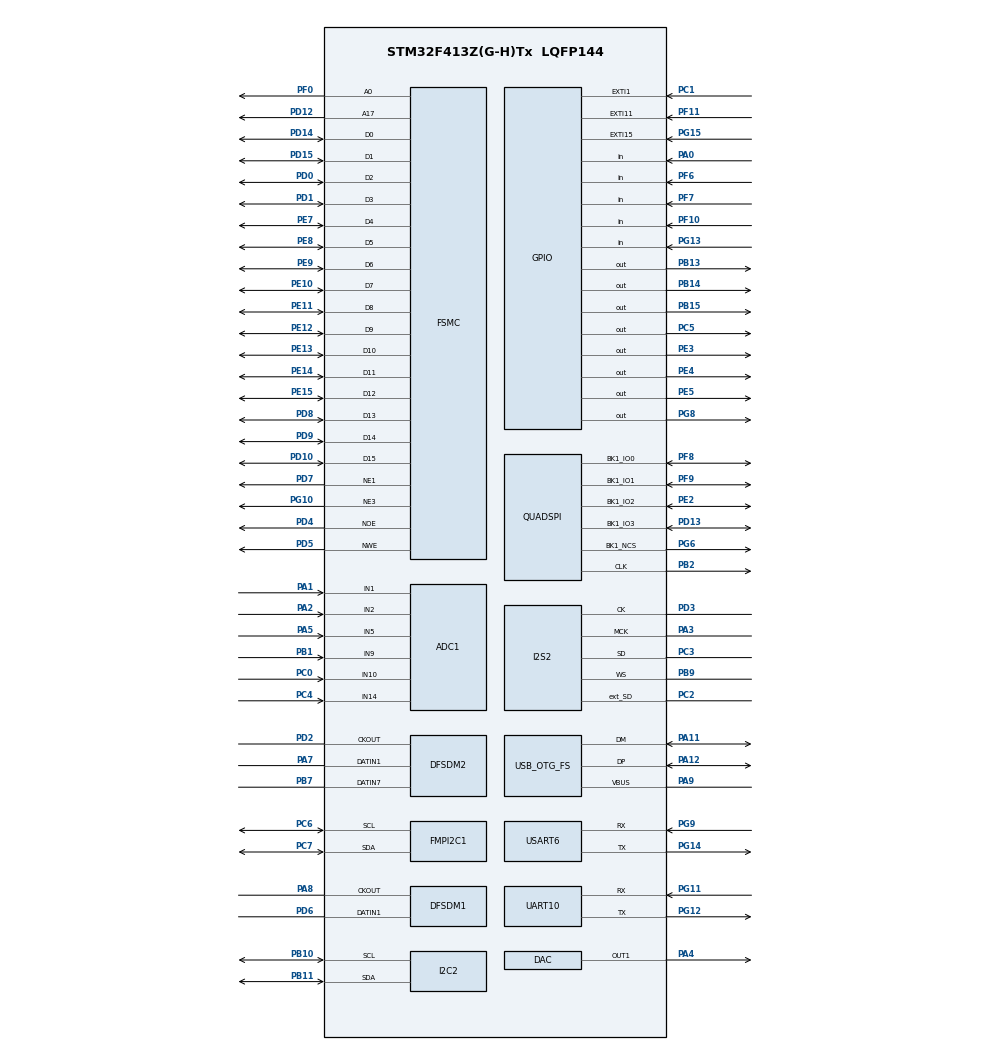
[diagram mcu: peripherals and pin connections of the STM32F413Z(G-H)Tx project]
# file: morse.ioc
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SH.FSMC_D1_DA1.1=FSMC_D1,16b-d2
PD7.Mode=NorPsramChipSelect1_1
PF5.GPIO_PuPd=GPIO_NOPULL
PG8.GPIO_ModeDefaultOutputPP=GPIO_MODE_OUTPUT_PP
SH.FSMC_D1_DA1.0=FSMC_D1,16b-d1
PC10.GPIO_PuPd=GPIO_NOPULL
NVIC.TIM6_DAC_IRQn=true\:0\:0\:false\:false\:true\:false\:false\:true
PA10.GPIO_PuPd=GPIO_NOPULL
PG8.Signal=GPIO_Output
SH.FSMC_NWE.0=FSMC_NWE,Lcd1
PG0.Signal=FSMC_A10
PA3.GPIO_PuPd=GPIO_NOPULL
SH.FSMC_NWE.1=FSMC_NWE,Lcd2
PE8.GPIO_Speed_High_Default=GPIO_SPEED_FREQ_VERY_HIGH
PE10.GPIO_PuPd=GPIO_NOPULL
PD10.GPIO_PuPd=GPIO_NOPULL
USB_HOST.USBH_USE_OS-CDC_FS=0
PG10.GPIO_PuPd=GPIO_NOPULL
PA6.GPIO_Mode=GPIO_MODE_AF_PP
PD0.GPIO_Speed_High_Default=GPIO_SPEED_FREQ_VERY_HIGH
PE13.GPIO_Mode=GPIO_MODE_AF_PP
PF13.GPIO_Mode=GPIO_MODE_AF_PP
PF7.Signal=GPIO_Input
PD13.GPIO_Mode=GPIO_MODE_AF_PP
PD7.GPIO_PuPd=GPIO_NOPULL
PD9.GPIO_Speed_High_Default=GPIO_SPEED_FREQ_VERY_HIGH
PC4.GPIO_Mode=GPIO_MODE_ANALOG
PC7.Signal=FMPI2C1_SDA
PD0.Signal=FSMC_D2_DA2
PD8.Signal=FSMC_D13_DA13
PE1.Signal=FSMC_NBL1
PG5.GPIO_Speed_High_Default=GPIO_SPEED_FREQ_VERY_HIGH
USB_OTG_FS.phy_itface=HCD_PHY_EMBEDDED
PC1.GPIO_PuPd=GPIO_NOPULL
PG14.Mode=Asynchronous
SH.FSMC_D10_DA10.0=FSMC_D10,16b-d1
PE9.Signal=FSMC_D6_DA6
SH.FSMC_D10_DA10.1=FSMC_D10,16b-d2
PD14.GPIO_PuPd=GPIO_NOPULL
PA8.Signal=S_CKOUTDFSDM1
PG4.GPIO_Speed_High_Default=GPIO_SPEED_FREQ_VERY_HIGH
PF1.GPIO_Mode=GPIO_MODE_AF_PP
PF14.GPIO_PuPd=GPIO_NOPULL
SH.FSMC_D5_DA5.0=FSMC_D5,16b-d1
PG0.GPIO_PuPd=GPIO_NOPULL
PB2.GPIO_PuPd=GPIO_NOPULL
SH.FSMC_D5_DA5.1=FSMC_D5,16b-d2
PA0.Signal=GPIO_Input
PE9.GPIO_Mode=GPIO_MODE_AF_PP
Mcu.Package=LQFP144
PE2.GPIO_Mode=GPIO_MODE_AF_PP
PB9.Signal=I2S2_WS
PB1.Signal=ADCx_IN9
PB14.GPIO_PuPd=GPIO_NOPULL
NVIC.TimeBase=TIM6_DAC_IRQn
PD12.Signal=FSMC_A17
PG3.GPIO_Mode=GPIO_MODE_AF_PP
NVIC.TimeBaseIP=TIM6
PA10.Signal=USB_OTG_FS_ID
PB9.GPIO_PuPd=GPIO_NOPULL
SH.FSMC_A1.0=FSMC_A1
PB5.GPIO_Speed=GPIO_SPEED_FREQ_VERY_HIGH
PG8.GPIO_Speed=GPIO_SPEED_FREQ_LOW
PD3.GPIO_PuPd=GPIO_NOPULL
PF9.GPIO_PuPd=GPIO_NOPULL
PE6.GPIO_PuPd=GPIO_NOPULL
PA8.GPIO_Speed=GPIO_SPEED_FREQ_LOW
PD15.Signal=FSMC_D1_DA1
PE7.GPIO_Speed_High_Default=GPIO_SPEED_FREQ_VERY_HIGH
PC8.GPIO_Mode=GPIO_MODE_AF_PP
PG12.Signal=UART10_TX
PA2.GPIO_Mode=GPIO_MODE_ANALOG
PB5.GPIO_Mode=GPIO_MODE_AF_PP
FREERTOS.Tasks01=gameTask,24,128,gameHandler,Default,NULL,Dynamic,NULL,NULL;displayTask,8,128,displayHandler,Default,NULL,Dynamic,NULL,NULL;buttonTask,8,128,buttonHandler,Default,NULL,Dynamic,NULL,NULL;ledTask,8,128,ledHandler,Default,NULL,Dynamic,NULL,NULL;runIndicate,8,128,runIndicateHandler,Default,NULL,Dynamic,NULL,NULL
SH.FSMC_A16.0=FSMC_A16
PF4.GPIO_Mode=GPIO_MODE_AF_PP
PD1.GPIO_Speed_High_Default=GPIO_SPEED_FREQ_VERY_HIGH
PG5.Signal=FSMC_A15
PE9.GPIO_Speed_High_Default=GPIO_SPEED_FREQ_VERY_HIGH
PD3.Signal=I2S2_CK
SH.FSMC_D9_DA9.1=FSMC_D9,16b-d2
PH1\ -\ OSC_OUT.Mode=HSE-External-Clock-Source
PG9.Mode=Asynchronous
PC2.Signal=I2S2_ext_SD
SH.FSMC_D9_DA9.0=FSMC_D9,16b-d1
PC14-OSC32_IN.Signal=RCC_OSC32_IN
PF5.GPIO_Mode=GPIO_MODE_AF_PP
SH.FSMC_D8_DA8.0=FSMC_D8,16b-d1
SH.FSMC_D8_DA8.1=FSMC_D8,16b-d2
PG8.GPIO_PuPd=GPIO_NOPULL
PD10.Signal=FSMC_D15_DA15
PA3.Mode=Master_Clock_Activated
PC10.GPIO_Mode=GPIO_MODE_AF_PP
PE15.GPIO_Speed_High_Default=GPIO_SPEED_FREQ_VERY_HIGH
PB10.GPIO_Mode=GPIO_MODE_AF_OD
SH.FSMC_A3.0=FSMC_A3
PB1.GPIO_Mode=GPIO_MODE_ANALOG
PB13.GPIO_Speed=GPIO_SPEED_FREQ_LOW
PF5.GPIO_Speed_High_Default=GPIO_SPEED_FREQ_VERY_HIGH
PD7.GPIO_Mode=GPIO_MODE_AF_PP
PG10.GPIO_Mode=GPIO_MODE_AF_PP
PB14.Signal=GPIO_Output
PA5.Signal=ADCx_IN5
PE2.GPIO_PuPd=GPIO_NOPULL
PD14.GPIO_Speed_High_Default=GPIO_SPEED_FREQ_VERY_HIGH
PF13.GPIO_PuPd=GPIO_NOPULL
PB13.GPIO_PuPd=GPIO_NOPULL
PE14.Signal=FSMC_D11_DA11
PB2.GPIO_Mode=GPIO_MODE_AF_PP
PG15.GPIO_ModeDefaultEXTI=GPIO_MODE_IT_RISING
PC9.GPIO_PuPd=GPIO_NOPULL
PE3.GPIO_PuPd=GPIO_NOPULL
PF13.Signal=FSMC_A7
PG14.GPIO_PuPd=GPIO_NOPULL
PC8.GPIO_PuPd=GPIO_NOPULL
ADC1.master=1
PB5.GPIO_PuPd=GPIO_NOPULL
ProjectManager.HeapSize=0x200
PD0.GPIO_PuPd=GPIO_NOPULL
PG12.GPIO_Speed=GPIO_SPEED_FREQ_VERY_HIGH
USB_HOST.USBH_HandleTypeDef=hUsbHostFS
NVIC.PriorityGroup=NVIC_PRIORITYGROUP_4
SH.FSMC_A5.0=FSMC_A5
PC5.GPIO_Speed=GPIO_SPEED_FREQ_LOW
PC1.GPIO_ModeDefaultEXTI=GPIO_MODE_IT_RISING
PE3.Signal=GPIO_Output
PE4.PinState=GPIO_PIN_RESET
PA6.GPIO_Speed_High_Default=GPIO_SPEED_FREQ_VERY_HIGH
PF4.Signal=FSMC_A4
PD2.Signal=S_CKOUTDFSDM2
PD14.GPIO_Mode=GPIO_MODE_AF_PP
Mcu.Family=STM32F4
PD7.GPIO_Speed_High_Default=GPIO_SPEED_FREQ_VERY_HIGH
FREERTOS.BinarySemaphores01=displaySemEMPTY,Dynamic,NULL;displaySemFULL,Dynamic,NULL;buttonSemFULL,Dynamic,NULL;buttonSemEMPTY,Dynamic,NULL;ledSemFULL,Dynamic,NULL;ledSEMEmpty,Dynamic,NULL
SH.FSMC_A6.0=FSMC_A6
PG2.Signal=FSMC_A12
PB2.GPIO_Speed=GPIO_SPEED_FREQ_VERY_HIGH
PA7.GPIO_Mode=GPIO_MODE_AF_PP
SH.FSMC_D0_DA0.1=FSMC_D0,16b-d2
PE2.GPIO_Speed=GPIO_SPEED_FREQ_VERY_HIGH
SH.FSMC_D0_DA0.0=FSMC_D0,16b-d1
PA11.Mode=Host_Only
PF9.GPIO_Speed=GPIO_SPEED_FREQ_VERY_HIGH
PD2.GPIO_Mode=GPIO_MODE_AF_PP
PC2.GPIO_Speed=GPIO_SPEED_FREQ_LOW
PG9.GPIO_Speed=GPIO_SPEED_FREQ_VERY_HIGH
PD8.GPIO_PuPd=GPIO_NOPULL
PB15.Signal=GPIO_Output
PG11.Signal=UART10_RX
PG15.Signal=GPXTI15
PG3.GPIO_PuPd=GPIO_NOPULL
PD13.Signal=QUADSPI_BK1_IO3
SH.S_DATAIN7DFSDM2.0=DFSDM2_DATIN7,Manchester_input_from_ch7
PC11.GPIO_PuPd=GPIO_NOPULL
SH.FSMC_A11.0=FSMC_A11
PH0\ -\ OSC_IN.Signal=RCC_OSC_IN
PE11.GPIO_PuPd=GPIO_NOPULL
PF11.GPIO_PuPd=GPIO_NOPULL
PB1.GPIO_PuPd=GPIO_NOPULL
PG5.GPIO_PuPd=GPIO_NOPULL
USB_HOST0.BSP.ip=GPIO
PA15.GPIO_ModeDefaultPP=GPIO_MODE_AF_PP
PF15.GPIO_Speed_High_Default=GPIO_SPEED_FREQ_VERY_HIGH
PE3.PinState=GPIO_PIN_RESET
PD4.GPIO_Mode=GPIO_MODE_AF_PP
PA9.GPIO_Mode=GPIO_MODE_INPUT
ADC1.Channel-0\#ChannelRegularConversion=ADC_CHANNEL_10
PA4.GPIO_PuPd=GPIO_NOPULL
PE13.GPIO_PuPd=GPIO_NOPULL
SH.FSMC_NBL0.0=FSMC_NBL0
PG11.GPIO_Speed=GPIO_SPEED_FREQ_VERY_HIGH
PA6.GPIO_PuPd=GPIO_NOPULL
SH.FSMC_D14_DA14.1=FSMC_D14,16b-d2
PF9.Mode=Single Bank 1
SH.FSMC_D14_DA14.0=FSMC_D14,16b-d1
PC14-OSC32_IN.Mode=LSE-External-Oscillator
PF8.GPIO_PuPd=GPIO_NOPULL
PA14.Mode=Serial_Wire
PF11.Signal=GPXTI11
SH.FSMC_D6_DA6.0=FSMC_D6,16b-d1
SH.FSMC_D6_DA6.1=FSMC_D6,16b-d2
PC7.GPIO_Mode=GPIO_MODE_AF_OD
SH.FSMC_A8.0=FSMC_A8
PB7.Signal=S_DATAIN7DFSDM2
PG4.GPIO_Mode=GPIO_MODE_AF_PP
SH.FSMC_D4_DA4.1=FSMC_D4,16b-d2
SH.FSMC_D4_DA4.0=FSMC_D4,16b-d1
PD6.GPIO_Mode=GPIO_MODE_AF_PP
PB12.GPIO_Mode=GPIO_MODE_AF_PP
PA6.Signal=SDIO_CMD
PB15.GPIO_PuPd=GPIO_NOPULL
PG2.GPIO_Speed_High_Default=GPIO_SPEED_FREQ_VERY_HIGH
USART6.VirtualMode=VM_ASYNC
NVIC.OTG_FS_IRQn=true\:0\:0\:false\:false\:true\:true\:true\:true
PG1.GPIO_PuPd=GPIO_NOPULL
FMPI2C1.Timing=0x00303D5B
SH.FSMC_D13_DA13.0=FSMC_D13,16b-d1
SH.FSMC_D13_DA13.1=FSMC_D13,16b-d2
PA15.Signal=S_TIM2_CH1_ETR
PF8.Signal=QUADSPI_BK1_IO0
SH.FSMC_A13.0=FSMC_A13
PA10.GPIO_Speed=GPIO_SPEED_FREQ_VERY_HIGH
USB_HOST0.BSP.name=Drive_VBUS_FS
SH.ADCx_IN1.0=ADC1_IN1,IN1
PD0.GPIO_Mode=GPIO_MODE_AF_PP
SH.FSMC_D2_DA2.1=FSMC_D2,16b-d2
SH.FSMC_D2_DA2.0=FSMC_D2,16b-d1
PC5.Signal=GPIO_Output
PE14.GPIO_Mode=GPIO_MODE_AF_PP
PE7.Signal=FSMC_D4_DA4
PD6.Signal=S_DATAIN1DFSDM1
SH.S_DATAIN1DFSDM1.0=DFSDM1_DATIN1,Manchester_input_from_ch1
PA12.GPIO_Speed=GPIO_SPEED_FREQ_VERY_HIGH
PB4.Signal=SPI3_MISO
PA3.Signal=I2S2_MCK
PE0.GPIO_PuPd=GPIO_NOPULL
PG1.GPIO_Mode=GPIO_MODE_AF_PP
SH.FSMC_D12_DA12.0=FSMC_D12,16b-d1
SH.FSMC_D12_DA12.1=FSMC_D12,16b-d2
PC11.Signal=SDIO_D3
PD12.GPIO_Speed_High_Default=GPIO_SPEED_FREQ_VERY_HIGH
PC8.Signal=SDIO_D0
USB_HOST0.BSP.solution=PG8
PC2.Mode=Full_Duplex_Master
PD9.Signal=FSMC_D14_DA14
PD8.GPIO_Speed_High_Default=GPIO_SPEED_FREQ_VERY_HIGH
SH.S_TIM3_CH3.0=TIM3_CH3
PA9.GPIO_PuPd=GPIO_NOPULL
PB0.GPIO_Speed=GPIO_SPEED_FREQ_LOW
PA13.Signal=SYS_JTMS-SWDIO
PD4.GPIO_PuPd=GPIO_NOPULL
PA9.Mode=Activate_VBUS
PH0\ -\ OSC_IN.Mode=HSE-External-Clock-Source
PB14.PinState=GPIO_PIN_RESET
PF6.Signal=GPIO_Input
PC9.GPIO_Mode=GPIO_MODE_AF_PP
PF0.GPIO_Speed_High_Default=GPIO_SPEED_FREQ_VERY_HIGH
PA3.GPIO_Mode=GPIO_MODE_AF_PP
SH.S_TIM4_CH3.0=TIM4_CH3
PB9.Mode=Full_Duplex_Master
PG2.GPIO_Mode=GPIO_MODE_AF_PP
RCC.USBFreq_Value=48000000
PB14.GPIO_ModeDefaultOutputPP=GPIO_MODE_OUTPUT_PP
PA7.GPIO_PuPd=GPIO_NOPULL
PA1.Signal=ADCx_IN1
PE10.GPIO_Speed_High_Default=GPIO_SPEED_FREQ_VERY_HIGH
PE10.GPIO_Mode=GPIO_MODE_AF_PP
board=STM32F413H-DISCO
PD13.GPIO_Speed=GPIO_SPEED_FREQ_VERY_HIGH
PG12.Mode=Asynchronous
PC7.GPIO_Speed=GPIO_SPEED_FREQ_VERY_HIGH
RCC.VCOOutputFreq_Value=240000000
PA4.GPIO_Mode=GPIO_MODE_ANALOG
PG3.GPIO_Speed_High_Default=GPIO_SPEED_FREQ_VERY_HIGH
PE11.GPIO_Mode=GPIO_MODE_AF_PP
PD5.GPIO_PuPd=GPIO_NOPULL
PE14.GPIO_PuPd=GPIO_NOPULL
PF1.Signal=FSMC_A1
PF8.GPIO_Mode=GPIO_MODE_AF_PP
PE0.Signal=FSMC_NBL0
PE12.Signal=FSMC_D9_DA9
PE12.GPIO_Mode=GPIO_MODE_AF_PP
I2S2.ErrorAudioFreq=1.72 %
VP_USB_HOST_VS_USB_HOST_CDC_FS.Mode=CDC_FS
PB2.Mode=Single Bank 1
PA15.GPIO_Speed=GPIO_SPEED_FREQ_LOW
PE15.GPIO_PuPd=GPIO_NOPULL
PE5.GPIO_ModeDefaultOutputPP=GPIO_MODE_OUTPUT_PP
SH.FSMC_D11_DA11.1=FSMC_D11,16b-d2
SH.FSMC_D11_DA11.0=FSMC_D11,16b-d1
SH.FSMC_NOE.1=FSMC_NOE,Lcd2
PG4.GPIO_PuPd=GPIO_NOPULL
SH.FSMC_NOE.0=FSMC_NOE,Lcd1
PD3.GPIO_Mode=GPIO_MODE_AF_PP
PA8.GPIO_PuPd=GPIO_NOPULL
PF9.GPIO_Mode=GPIO_MODE_AF_PP
SH.S_CKOUTDFSDM2.0=DFSDM2_CKOUT,CKOUT
RCC.PLLQ=5
RCC.PLLM=15
RCC.PLLN=144
PE5.GPIO_Speed=GPIO_SPEED_FREQ_LOW
PG0.GPIO_Mode=GPIO_MODE_AF_PP
PA5.GPIO_Mode=GPIO_MODE_ANALOG
PB8.GPIO_Speed=GPIO_SPEED_FREQ_LOW
PD6.GPIO_Speed=GPIO_SPEED_FREQ_LOW
PG14.GPIO_Speed=GPIO_SPEED_FREQ_VERY_HIGH
I2S2.RealAudioFreq=8.138 KHz
RCC.PLLI2SN=50
PB12.Signal=SPI3_SCK
PB0.GPIO_PuPd=GPIO_NOPULL
RCC.PLLI2SM=12
PD6.GPIO_PuPd=GPIO_NOPULL
USB_HOST0.BSP.instance=PG8
PA11.GPIO_Speed=GPIO_SPEED_FREQ_VERY_HIGH
PF15.GPIO_Mode=GPIO_MODE_AF_PP
PE15.GPIO_Mode=GPIO_MODE_AF_PP
PG14.GPIO_ModeDefaultPP=GPIO_MODE_AF_PP
PD1.GPIO_Mode=GPIO_MODE_AF_PP
PD15.GPIO_Mode=GPIO_MODE_AF_PP
VP_SYS_VS_tim6.Mode=TIM6
PE4.GPIO_ModeDefaultOutputPP=GPIO_MODE_OUTPUT_PP
PG2.GPIO_PuPd=GPIO_NOPULL
PB10.Mode=I2C
PD11.GPIO_Speed_High_Default=GPIO_SPEED_FREQ_VERY_HIGH
PA8.GPIO_Mode=GPIO_MODE_AF_PP
PG4.Signal=FSMC_A14
PC12.Signal=SDIO_CK
PE8.GPIO_PuPd=GPIO_NOPULL
PC6.GPIO_PuPdOD=GPIO_PULLUP
PC7.GPIO_PuPdOD=GPIO_PULLUP
PA3.GPIO_Speed=GPIO_SPEED_FREQ_LOW
PB13.Signal=GPIO_Output
PD3.GPIO_Speed=GPIO_SPEED_FREQ_LOW
PG6.Mode=Single Bank 1
PG13.Signal=GPIO_Input
PC3.GPIO_Speed=GPIO_SPEED_FREQ_LOW
PB11.GPIO_Speed=GPIO_SPEED_FREQ_VERY_HIGH
PB7.GPIO_Mode=GPIO_MODE_AF_PP
PC10.GPIO_Speed_High_Default=GPIO_SPEED_FREQ_VERY_HIGH
PD5.GPIO_Speed_High_Default=GPIO_SPEED_FREQ_VERY_HIGH
PE2.Mode=Single Bank 1
PD4.Signal=FSMC_NOE
PC3.Signal=I2S2_SD
PB15.GPIO_ModeDefaultOutputPP=GPIO_MODE_OUTPUT_PP
PE5.Signal=GPIO_Output
PG0.GPIO_Speed_High_Default=GPIO_SPEED_FREQ_VERY_HIGH
PA1.GPIO_PuPd=GPIO_NOPULL
PB2.Signal=QUADSPI_CLK
PE11.GPIO_Speed_High_Default=GPIO_SPEED_FREQ_VERY_HIGH
PG6.GPIO_PuPd=GPIO_NOPULL
SH.FSMC_A0.0=FSMC_A0,A0_2
PA5.GPIO_PuPd=GPIO_NOPULL
PD11.GPIO_Mode=GPIO_MODE_AF_PP
PE5.PinState=GPIO_PIN_RESET
PD5.GPIO_Mode=GPIO_MODE_AF_PP
PF13.GPIO_Speed_High_Default=GPIO_SPEED_FREQ_VERY_HIGH
PE2.Signal=QUADSPI_BK1_IO2
PF8.Mode=Single Bank 1
PF3.Signal=FSMC_A3
PD3.Mode=Full_Duplex_Master
PE10.Signal=FSMC_D7_DA7
PF1.GPIO_Speed_High_Default=GPIO_SPEED_FREQ_VERY_HIGH
PE6.GPIO_ModeDefaultPP=GPIO_MODE_AF_PP
ADC1.SamplingTime-0\#ChannelRegularConversion=ADC_SAMPLETIME_3CYCLES
SH.ADCx_IN14.0=ADC1_IN14,IN14
PF3.GPIO_PuPd=GPIO_NOPULL
SH.ADCx_IN9.0=ADC1_IN9,IN9
SH.FSMC_D3_DA3.1=FSMC_D3,16b-d2
SH.FSMC_D3_DA3.0=FSMC_D3,16b-d1
PC2.GPIO_Mode=GPIO_MODE_AF_PP
PG12.GPIO_PuPd=GPIO_PULLUP
PF14.Signal=FSMC_A8
PC12.GPIO_PuPd=GPIO_NOPULL
PB11.GPIO_Mode=GPIO_MODE_AF_OD
PA12.GPIO_PuPd=GPIO_NOPULL
PD9.GPIO_PuPd=GPIO_NOPULL
PE6.GPIO_Speed=GPIO_SPEED_FREQ_LOW
PC6.GPIO_Speed=GPIO_SPEED_FREQ_VERY_HIGH
PG6.GPIO_Speed=GPIO_SPEED_FREQ_VERY_HIGH
PE12.GPIO_PuPd=GPIO_NOPULL
PD8.GPIO_Mode=GPIO_MODE_AF_PP
PB7.GPIO_PuPd=GPIO_NOPULL
ADC1.Rank-0\#ChannelRegularConversion=1
SH.FSMC_A2.0=FSMC_A2
PA1.GPIO_Mode=GPIO_MODE_ANALOG
PD2.GPIO_PuPd=GPIO_NOPULL
PG9.GPIO_PuPd=GPIO_NOPULL
PG9.Signal=USART6_RX
PB10.GPIO_PuPdOD=GPIO_PULLUP
PB11.GPIO_PuPdOD=GPIO_PULLUP
PD9.GPIO_Mode=GPIO_MODE_AF_PP
PB8.GPIO_PuPd=GPIO_NOPULL
PC6.Signal=FMPI2C1_SCL
PD7.Signal=FSMC_NE1
PD1.Signal=FSMC_D3_DA3
PE1.GPIO_PuPd=GPIO_NOPULL
PD1.GPIO_PuPd=GPIO_NOPULL
PC0.Signal=ADCx_IN10
PG1.GPIO_Speed_High_Default=GPIO_SPEED_FREQ_VERY_HIGH
PG10.Signal=FSMC_NE3
PD10.GPIO_Speed_High_Default=GPIO_SPEED_FREQ_VERY_HIGH
USB_HOST0.BSP.STBoard=false
PF2.GPIO_Mode=GPIO_MODE_AF_PP
PB11.Mode=I2C
PB14.GPIO_Speed=GPIO_SPEED_FREQ_LOW
SH.FSMC_A15.0=FSMC_A15
SH.S_TIM9_CH2.0=TIM9_CH2
PC6.Mode=I2C
PA9.Signal=USB_OTG_FS_VBUS
I2S2.VirtualMode=I2S_MODE_MASTER
PB4.GPIO_PuPd=GPIO_NOPULL
PB10.Signal=I2C2_SCL
SH.FSMC_D7_DA7.1=FSMC_D7,16b-d2
PH1\ -\ OSC_OUT.Signal=RCC_OSC_OUT
SH.FSMC_D7_DA7.0=FSMC_D7,16b-d1
USB_HOST.VirtualModeFS=Cdc
PA7.GPIO_Speed=GPIO_SPEED_FREQ_LOW
RCC.SDIOCLockSelection=RCC_SDIOCLKSOURCE_SYSCLK
PD4.GPIO_Speed_High_Default=GPIO_SPEED_FREQ_VERY_HIGH
PB13.PinState=GPIO_PIN_RESET
PE15.Signal=FSMC_D12_DA12
PG11.GPIO_Mode=GPIO_MODE_AF_PP
PE8.Signal=FSMC_D5_DA5
PG5.GPIO_Mode=GPIO_MODE_AF_PP
PC11.GPIO_Mode=GPIO_MODE_AF_PP
SH.FSMC_A4.0=FSMC_A4
PC6.GPIO_Mode=GPIO_MODE_AF_OD
UART10.VirtualMode=Asynchronous
PA13.Mode=Serial_Wire
PG12.GPIO_Mode=GPIO_MODE_AF_PP
PF14.GPIO_Speed_High_Default=GPIO_SPEED_FREQ_VERY_HIGH
PE4.GPIO_PuPd=GPIO_NOPULL
I2S2.FullDuplexMode=I2S_FULLDUPLEXMODE_ENABLE
PC12.GPIO_Speed_High_Default=GPIO_SPEED_FREQ_VERY_HIGH
PC8.GPIO_Speed_High_Default=GPIO_SPEED_FREQ_VERY_HIGH
PA4.Signal=COMP_DAC1_group
PC12.GPIO_Mode=GPIO_MODE_AF_PP
PB5.Signal=SPI3_MOSI
PE3.GPIO_Speed=GPIO_SPEED_FREQ_LOW
PE3.GPIO_ModeDefaultOutputPP=GPIO_MODE_OUTPUT_PP
PD11.Signal=FSMC_A16
PG11.Mode=Asynchronous
PA11.Signal=USB_OTG_FS_DM
SH.FSMC_D15_DA15.1=FSMC_D15,16b-d2
SH.S_TIM2_CH1_ETR.0=TIM2_CH1
SH.FSMC_D15_DA15.0=FSMC_D15,16b-d1
PE12.GPIO_Speed_High_Default=GPIO_SPEED_FREQ_VERY_HIGH
SH.FSMC_A17.0=FSMC_A17,A17_1
PF9.Signal=QUADSPI_BK1_IO1
FREERTOS.Timers01=problemTimeout,problemTimeoutCallback,osTimerOnce,Default,NULL,Dynamic,NULL;dotTimer,dotCallback,osTimerOnce,Default,NULL,Dynamic,NULL;dashTimer,dashCallback,osTimerOnce,Default,NULL,Dynamic,NULL
SH.ADCx_IN5.0=ADC1_IN5,IN5
FREERTOS.Mutexes01=displayMutex,Dynamic,NULL;ledMutex,Dynamic,NULL;buttonMutex,Dynamic,NULL
PF12.GPIO_PuPd=GPIO_NOPULL
PB12.GPIO_PuPd=GPIO_NOPULL
PG6.GPIO_Mode=GPIO_MODE_AF_PP
PB0.Signal=S_TIM3_CH3
USB_HOST0.BSP.mode=Output
PE0.GPIO_Mode=GPIO_MODE_AF_PP
PC1.Signal=GPXTI1
PF3.GPIO_Mode=GPIO_MODE_AF_PP
PG15.GPIO_PuPd=GPIO_NOPULL
PF2.GPIO_Speed_High_Default=GPIO_SPEED_FREQ_VERY_HIGH
PC3.Mode=Full_Duplex_Master
PC3.GPIO_Mode=GPIO_MODE_AF_PP
PA2.GPIO_PuPd=GPIO_NOPULL
PE7.GPIO_PuPd=GPIO_NOPULL
RCC.CortexFreq_Value=16000000
PG6.Signal=QUADSPI_BK1_NCS
SH.FSMC_A12.0=FSMC_A12
PB10.GPIO_Speed=GPIO_SPEED_FREQ_VERY_HIGH
PF4.GPIO_Speed_High_Default=GPIO_SPEED_FREQ_VERY_HIGH
SH.ADCx_IN2.0=ADC1_IN2,IN2
PC10.Signal=SDIO_D2
PF4.GPIO_PuPd=GPIO_NOPULL
PD2.GPIO_Speed=GPIO_SPEED_FREQ_LOW
SH.S_DATAIN1DFSDM2.0=DFSDM2_DATIN1,Manchester_input_from_ch1
PA11.GPIO_PuPd=GPIO_NOPULL
PE14.GPIO_Speed_High_Default=GPIO_SPEED_FREQ_VERY_HIGH
PB11.Signal=I2C2_SDA
PB15.PinState=GPIO_PIN_RESET
ProjectManager.StackSize=0x400
VP_FREERTOS_VS_CMSIS_V2.Mode=CMSIS_V2
PD11.GPIO_PuPd=GPIO_NOPULL
PA12.Signal=USB_OTG_FS_DP
PB4.GPIO_Mode=GPIO_MODE_AF_PP
PE5.GPIO_PuPd=GPIO_NOPULL
SH.FSMC_A7.0=FSMC_A7
PE1.GPIO_Mode=GPIO_MODE_AF_PP
PG11.GPIO_PuPd=GPIO_PULLUP
PB13.GPIO_ModeDefaultOutputPP=GPIO_MODE_OUTPUT_PP
PF2.GPIO_PuPd=GPIO_NOPULL
PF12.Signal=FSMC_A6
PF11.GPIO_ModeDefaultEXTI=GPIO_MODE_IT_RISING
SH.FSMC_A10.0=FSMC_A10
PC9.GPIO_Speed_High_Default=GPIO_SPEED_FREQ_VERY_HIGH
PB8.GPIO_ModeDefaultPP=GPIO_MODE_AF_PP
PE13.Signal=FSMC_D10_DA10
SH.FSMC_A14.0=FSMC_A14
PE0.GPIO_Speed_High_Default=GPIO_SPEED_FREQ_VERY_HIGH
PE4.GPIO_Speed=GPIO_SPEED_FREQ_LOW
USB_HOST0.BSP.i2creg=0
PE4.Signal=GPIO_Output
PF12.GPIO_Mode=GPIO_MODE_AF_PP
PD12.GPIO_Mode=GPIO_MODE_AF_PP
USB_HOST0.BSP.i2caddr=0
SH.FSMC_NBL1.0=FSMC_NBL1
PF15.GPIO_PuPd=GPIO_NOPULL
PD15.GPIO_PuPd=GPIO_NOPULL
USB_OTG_FS.VirtualMode=Host_Only
PF3.GPIO_Speed_High_Default=GPIO_SPEED_FREQ_VERY_HIGH
PE8.GPIO_Mode=GPIO_MODE_AF_PP
PF5.Signal=FSMC_A5
PB9.GPIO_Speed=GPIO_SPEED_FREQ_LOW
PG8.PinState=GPIO_PIN_RESET
SH.FSMC_A9.0=FSMC_A9
PE13.GPIO_Speed_High_Default=GPIO_SPEED_FREQ_VERY_HIGH
PF0.Signal=FSMC_A0
PC0.GPIO_PuPd=GPIO_NOPULL
PG9.GPIO_ModeDefaultPP=GPIO_MODE_AF_PP
PF0.GPIO_Mode=GPIO_MODE_AF_PP
PB7.GPIO_Speed=GPIO_SPEED_FREQ_LOW
PC15-OSC32_OUT.Mode=LSE-External-Oscillator
SH.COMP_DAC1_group.0=DAC_OUT1,DAC_OUT1
I2S2.Instance=SPI$Index
PG3.Signal=FSMC_A13
PC4.GPIO_PuPd=GPIO_NOPULL
PG1.Signal=FSMC_A11
PC4.Signal=ADCx_IN14
PG10.Mode=NorPsramChipSelect3_2
USB_HOST.BSP.number=1
PD5.Signal=FSMC_NWE
PC5.GPIO_PuPd=GPIO_NOPULL
PA10.GPIO_Mode=GPIO_MODE_AF_PP
PD10.GPIO_Mode=GPIO_MODE_AF_PP
PD15.GPIO_Speed_High_Default=GPIO_SPEED_FREQ_VERY_HIGH
ProjectManager.TargetToolchain=Makefile
PD13.Mode=Single Bank 1
PC11.GPIO_Speed_High_Default=GPIO_SPEED_FREQ_VERY_HIGH
PF2.Signal=FSMC_A2
PE11.Signal=FSMC_D8_DA8
PC15-OSC32_OUT.Signal=RCC_OSC32_OUT
PE7.GPIO_Mode=GPIO_MODE_AF_PP
PB12.GPIO_Speed=GPIO_SPEED_FREQ_VERY_HIGH
PG14.Signal=USART6_TX
PB0.GPIO_ModeDefaultPP=GPIO_MODE_AF_PP
PB9.GPIO_Mode=GPIO_MODE_AF_PP
PA12.GPIO_Mode=GPIO_MODE_AF_PP
PB4.GPIO_Speed=GPIO_SPEED_FREQ_VERY_HIGH
USB_HOST0.BSP.api=Unknown
PC0.GPIO_Mode=GPIO_MODE_ANALOG
PF10.Signal=GPIO_Input
PB15.GPIO_Speed=GPIO_SPEED_FREQ_LOW
SH.S_CKOUTDFSDM1.0=DFSDM1_CKOUT,CKOUT
PF1.GPIO_PuPd=GPIO_NOPULL
PG10.GPIO_Speed_High_Default=GPIO_SPEED_FREQ_VERY_HIGH
PD13.GPIO_PuPd=GPIO_NOPULL
PE1.GPIO_Speed_High_Default=GPIO_SPEED_FREQ_VERY_HIGH
PF15.Signal=FSMC_A9
PC2.GPIO_PuPd=GPIO_NOPULL
PE6.Signal=S_TIM9_CH2
Mcu.Name=STM32F413Z(G-H)Tx
PA2.Signal=ADCx_IN2
PD14.Signal=FSMC_D0_DA0
PB3.Signal=SYS_JTDO-SWO
PF0.GPIO_PuPd=GPIO_NOPULL
PC5.PinState=GPIO_PIN_RESET
PA12.Mode=Host_Only
PF12.GPIO_Speed_High_Default=GPIO_SPEED_FREQ_VERY_HIGH
PA14.Signal=SYS_JTCK-SWCLK
SH.ADCx_IN10.0=ADC1_IN10,IN10
ADC1.NbrOfConversionFlag=1
PF8.GPIO_Speed=GPIO_SPEED_FREQ_VERY_HIGH
PA15.GPIO_PuPd=GPIO_NOPULL
PB8.Signal=S_TIM4_CH3
PF14.GPIO_Mode=GPIO_MODE_AF_PP
PC9.Signal=SDIO_D1
PC7.Mode=I2C
PA11.GPIO_Mode=GPIO_MODE_AF_PP
PC5.GPIO_ModeDefaultOutputPP=GPIO_MODE_OUTPUT_PP
PC3.GPIO_PuPd=GPIO_NOPULL
PD12.GPIO_PuPd=GPIO_NOPULL
PA7.Signal=S_DATAIN1DFSDM2
PE9.GPIO_PuPd=GPIO_NOPULL

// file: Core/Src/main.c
/* USER CODE BEGIN Header */
/**
 ******************************************************************************
 * @file           : main.c
 * @brief          : Main program body
 ******************************************************************************
 * @attention
 *
 * <h2><center>&copy; Copyright (c) 2022 STMicroelectronics.
 * All rights reserved.</center></h2>
 *
 * This software component is licensed by ST under Ultimate Liberty license
 * SLA0044, the "License"; You may not use this file except in compliance with
 * the License. You may obtain a copy of the License at:
 *                             www.st.com/SLA0044
 *
 ******************************************************************************
 */
/* USER CODE END Header */
#include "main.h"
#include "cmsis_os.h"
#include "usb_host.h"

/* USER CODE BEGIN Includes */
#include "stm32f413h_discovery_lcd.h"
#include <stdbool.h>
#include "game_dictionary.h"
#include "string.h"
#include <math.h>
/* USER CODE END Includes */

/* USER CODE BEGIN PM */
#define DEBUG
#undef DEBUG // Comment to enable led running flashing
/* USER CODE END PM */

ADC_HandleTypeDef hadc1;

DAC_HandleTypeDef hdac;

DFSDM_Channel_HandleTypeDef hdfsdm1_channel1;
DFSDM_Channel_HandleTypeDef hdfsdm2_channel1;
DFSDM_Channel_HandleTypeDef hdfsdm2_channel7;

FMPI2C_HandleTypeDef hfmpi2c1;

I2C_HandleTypeDef hi2c2;

I2S_HandleTypeDef hi2s2;

QSPI_HandleTypeDef hqspi;

UART_HandleTypeDef huart10;
UART_HandleTypeDef huart6;

SRAM_HandleTypeDef hsram1;
SRAM_HandleTypeDef hsram2;

/* Definitions for gameTask */
osThreadId_t gameTaskHandle;
const osThreadAttr_t gameTask_attributes = {
    .name = "gameTask",
    .priority = (osPriority_t)osPriorityNormal,
    .stack_size = 128 * 4};
/* Definitions for displayTask */
osThreadId_t displayTaskHandle;
const osThreadAttr_t displayTask_attributes = {
    .name = "displayTask",
    .priority = (osPriority_t)osPriorityLow,
    .stack_size = 128 * 4};
/* Definitions for buttonTask */
osThreadId_t buttonTaskHandle;
const osThreadAttr_t buttonTask_attributes = {
    .name = "buttonTask",
    .priority = (osPriority_t)osPriorityLow,
    .stack_size = 128 * 4};
/* Definitions for ledTask */
osThreadId_t ledTaskHandle;
const osThreadAttr_t ledTask_attributes = {
    .name = "ledTask",
    .priority = (osPriority_t)osPriorityLow,
    .stack_size = 128 * 4};
/* Definitions for runIndicate */
osThreadId_t runIndicateHandle;
const osThreadAttr_t runIndicate_attributes = {
    .name = "runIndicate",
    .priority = (osPriority_t)osPriorityLow,
    .stack_size = 128 * 4};
/* Definitions for problemTimeout */
osTimerId_t problemTimeoutHandle;
const osTimerAttr_t problemTimeout_attributes = {
    .name = "problemTimeout"};
/* Definitions for dotTimer */
osTimerId_t dotTimerHandle;
const osTimerAttr_t dotTimer_attributes = {
    .name = "dotTimer"};
/* Definitions for dashTimer */
osTimerId_t dashTimerHandle;
const osTimerAttr_t dashTimer_attributes = {
    .name = "dashTimer"};
/* Definitions for displayMutex */
osMutexId_t displayMutexHandle;
const osMutexAttr_t displayMutex_attributes = {
    .name = "displayMutex"};
/* Definitions for ledMutex */
osMutexId_t ledMutexHandle;
const osMutexAttr_t ledMutex_attributes = {
    .name = "ledMutex"};
/* Definitions for buttonMutex */
osMutexId_t buttonMutexHandle;
const osMutexAttr_t buttonMutex_attributes = {
    .name = "buttonMutex"};
/* Definitions for displaySemEMPTY */
osSemaphoreId_t displaySemEMPTYHandle;
const osSemaphoreAttr_t displaySemEMPTY_attributes = {
    .name = "displaySemEMPTY"};
/* Definitions for displaySemFULL */
osSemaphoreId_t displaySemFULLHandle;
const osSemaphoreAttr_t displaySemFULL_attributes = {
    .name = "displaySemFULL"};
/* Definitions for buttonSemFULL */
osSemaphoreId_t buttonSemFULLHandle;
const osSemaphoreAttr_t buttonSemFULL_attributes = {
    .name = "buttonSemFULL"};
/* Definitions for buttonSemEMPTY */
osSemaphoreId_t buttonSemEMPTYHandle;
const osSemaphoreAttr_t buttonSemEMPTY_attributes = {
    .name = "buttonSemEMPTY"};
/* Definitions for ledSemFULL */
osSemaphoreId_t ledSemFULLHandle;
const osSemaphoreAttr_t ledSemFULL_attributes = {
    .name = "ledSemFULL"};
/* Definitions for ledSEMEmpty */
osSemaphoreId_t ledSEMEmptyHandle;
const osSemaphoreAttr_t ledSEMEmpty_attributes = {
    .name = "ledSEMEmpty"};
/* USER CODE BEGIN PV */
MORSE A[] = {DOT, DASH, MORSE_NONE};
MORSE B[] = {DASH, DOT, DOT, DOT, MORSE_NONE};
MORSE C[] = {DASH, DOT, DASH, DOT, MORSE_NONE};
MORSE D[] = {DASH, DOT, DOT, MORSE_NONE};
MORSE E[] = {DOT, MORSE_NONE};
MORSE F[] = {DOT, DOT, DASH, DOT, MORSE_NONE};
MORSE G[] = {DASH, DASH, DOT, MORSE_NONE};
MORSE H[] = {DOT, DOT, DOT, DOT, MORSE_NONE};
MORSE I[] = {DOT, DOT, MORSE_NONE};
MORSE J[] = {DOT, DASH, DASH, DASH, MORSE_NONE};
MORSE K[] = {DASH, DOT, DASH, MORSE_NONE};
MORSE L[] = {DOT, DASH, DOT, DOT, MORSE_NONE};
MORSE M[] = {DASH, DASH, MORSE_NONE};
MORSE N[] = {DASH, DOT, MORSE_NONE};
MORSE O[] = {DASH, DASH, DASH, MORSE_NONE};
MORSE P[] = {DOT, DASH, DASH, DOT, MORSE_NONE};
MORSE Q[] = {DASH, DASH, DOT, DASH, MORSE_NONE};
MORSE R[] = {DOT, DASH, DOT, MORSE_NONE};
MORSE S[] = {DOT, DOT, DOT, MORSE_NONE};
MORSE T[] = {DASH, MORSE_NONE};
MORSE U[] = {DOT, DOT, DASH, MORSE_NONE};
MORSE V[] = {DOT, DOT, DOT, DASH, MORSE_NONE};
MORSE W[] = {DOT, DASH, DASH, MORSE_NONE};
MORSE X[] = {DASH, DOT, DOT, DASH, MORSE_NONE};
MORSE Y[] = {DASH, DOT, DASH, DASH, MORSE_NONE};
MORSE Z[] = {DASH, DASH, DOT, DOT, MORSE_NONE};

int userStreak = 0;
int userScore = 0;
int problemsDone = 0;

MORSE *letters[] = {A, B, C, D, E, F, G, H, I, J, K, L, M, N, O, P, Q, R, S, T, U, V, W, X, Y, Z};
MORSE ledBuffer = DOT;

GAME_STATES gameState = MAIN; // shared memory, written to only by game thread
PROBLEM_TYPES propblemState = WORD;

BUTTONS buttonBuffer = BUTTON_NONE; // shared memory

// shared memory about choices for a problem
// written to only by game thread
char choices[4][20];
int correctChoice = -1;
// written to only by button thread ?
int chosenChoice = -1;

uint16_t BUTTON_COLORS[] = {LCD_COLOR_BLUE, LCD_COLOR_RED, LCD_COLOR_YELLOW, LCD_COLOR_GREEN};

// Signaling definitions
static TaskHandle_t ledTaskNotify = NULL;

/* USER CODE END PV */

void SystemClock_Config(void);
static void MX_GPIO_Init(void);
static void MX_ADC1_Init(void);
static void MX_DAC_Init(void);
static void MX_DFSDM1_Init(void);
static void MX_DFSDM2_Init(void);
static void MX_FMPI2C1_Init(void);
static void MX_FSMC_Init(void);
static void MX_I2S2_Init(void);
static void MX_QUADSPI_Init(void);
static void MX_UART10_Init(void);
static void MX_USART6_UART_Init(void);
static void MX_I2C2_Init(void);
void gameHandler(void *argument);
void displayHandler(void *argument);
void buttonHandler(void *argument);
void ledHandler(void *argument);
void runIndicateHandler(void *argument);
void problemTimeoutCallback(void *argument);
void dotCallback(void *argument);
void dashCallback(void *argument);

/* USER CODE BEGIN PFP */
void TM_RNG_Init(void);
void TM_RNG_DeInit(void);
uint32_t TM_RNG_Get(void);
void gameMain(void);
void gameProblem(void);
void gameEnd(void);
void intToString(int, char *, int);
/* USER CODE END PFP */

/* USER CODE BEGIN 0 */
void intToString(int number, char *stringPointer, int maxSize)
{
  int numberOfDigits;
  if (number > 0)
  {
    numberOfDigits = (int)log10(number) + 1;
  }
  else
  {
    numberOfDigits = 1;
  }

  if (numberOfDigits >= maxSize)
  {
    numberOfDigits = maxSize - 1;
    number = (int)pow(10, maxSize - 1) - 1;
  }

  for (int i = numberOfDigits; i > 0; --i, number /= 10)
  {
    stringPointer[i - 1] = (number % 10) + '0';
  }
  stringPointer[numberOfDigits] = '\0';
}

void TM_RNG_Init(void)
{
  __HAL_RCC_RNG_CLK_ENABLE();
  RNG->CR |= RNG_CR_RNGEN;
}

void TM_RNG_DeInit(void)
{
  RNG->CR &= ~RNG_CR_RNGEN;
  __HAL_RCC_RNG_CLK_DISABLE();
}

uint32_t TM_RNG_Get(void)
{
  while (!(RNG->SR & (RNG_SR_DRDY)))
    ;
  return RNG->DR;
}

void gameMain()
{
  osSemaphoreAcquire(displaySemEMPTYHandle, osWaitForever);
  // TODO: Add main menu text to display buffer
  osSemaphoreRelease(displaySemFULLHandle);

  // clear any extra button presses
  osStatus_t status = osSemaphoreAcquire(buttonSemFULLHandle, 1);
  if (status != osErrorTimeout)
  {
    osSemaphoreRelease(buttonSemEMPTYHandle);
  }

  // Process button press
  osSemaphoreAcquire(buttonSemFULLHandle, osWaitForever);
  if (buttonBuffer == RED)
  {
    propblemState = WORD;
  }
  else
  {
    propblemState = CHARACTER;
  }

  gameState = PROBLEM_GENERATION;

  osSemaphoreRelease(buttonSemEMPTYHandle);
}

void gameProblemGeneration()
{
  if (propblemState == CHARACTER)
  {
    // generate random problem
    int allLetters[] = {0, 1, 2, 3, 4, 5, 6, 7, 8, 9, 10, 11, 12, 13, 14, 15,
                        16, 17, 18, 19, 20, 21, 22, 23, 24, 25};
    for (int i = 0; i < 4; i++)
    {
      int randI = i + TM_RNG_Get() % (26 - i);
      int temp = allLetters[i];
      allLetters[i] = allLetters[randI];
      allLetters[randI] = temp;
      choices[i][0] = (char)allLetters[i] + 'a';
      choices[i][1] = '\0';
    }
  }
  else
  {
    int choiceWordIndex[4];
    for (int i = 0; i < 4; i++)
    {
      int randI = TM_RNG_Get() % (numberOfCommonWords);

      // Check for duplicates
      for (int j = 0; j < i; j++)
      {
        if (choiceWordIndex[j] == randI)
        {
          randI = randI + 1;
          j = 0;
        }
      }
      choiceWordIndex[i] = randI;

      // copy common word to choices
      for (int j = 0; commonWords[randI][j] != '\0' && j < 20; j++)
      {
        choices[i][j] = commonWords[randI][j];
      }
    }
  }
  correctChoice = TM_RNG_Get() % 4;
  chosenChoice = -1;
  // I believe there's no strict need for a mutex or semaphore on
  //     the shared memory for choices info?
  gameState = PROBLEM;
}

void gameProblem()
{
  // Lock button press and display problem
  osSemaphoreAcquire(displaySemEMPTYHandle, osWaitForever);
  // int letterNum = TM_RNG_Get() % 26;

  // TODO: Add main menu text to display buffer
  osSemaphoreRelease(displaySemFULLHandle);

  for (int i = 0; choices[correctChoice][i] != '\0'; i++)
  {
    osDelay(500);
    char currentLetter = choices[correctChoice][i];
    MORSE *morseLetter = letters[currentLetter - 'a'];
    for (int j = 0; morseLetter[j] != MORSE_NONE; j++)
    {
      osSemaphoreAcquire(ledSEMEmptyHandle, osWaitForever);
      ledBuffer = morseLetter[j];
      osSemaphoreRelease(ledSemFULLHandle);
    }
  }
  // clear any extra button presses during led flashing
  osStatus_t status = osSemaphoreAcquire(buttonSemFULLHandle, 1);
  if (status != osErrorTimeout)
  {
    osSemaphoreRelease(buttonSemEMPTYHandle);
  }

  // Get next button press
  status = osSemaphoreAcquire(buttonSemFULLHandle, 10000);
  problemsDone++;
  if (status == osErrorTimeout)
  {
    chosenChoice = -1;
  }
  else
  {
    // Handle button press
    chosenChoice = (int)buttonBuffer - 1;
    if (chosenChoice == correctChoice)
    {
      userStreak++;
      userScore++;
    }
    else
    {
      userStreak = 0;
    }
    osSemaphoreRelease(buttonSemEMPTYHandle);
  }
  gameState = END;
}

void gameEnd()
{
  // display "would you like to play again?"
  osSemaphoreAcquire(displaySemEMPTYHandle, 0);
  osSemaphoreRelease(displaySemFULLHandle);

  // clear any extra button presses before diplay finished
  osStatus_t status = osSemaphoreAcquire(buttonSemFULLHandle, 1);
  if (status != osErrorTimeout)
  {
    osSemaphoreRelease(buttonSemEMPTYHandle);
  }

  // get button press
  status = osSemaphoreAcquire(buttonSemFULLHandle, 10000);

  if (status == osErrorTimeout)
  {
    // if timed out, don't play again, go to main menu
    gameState = MAIN;
  }
  else
  {
    // depending on which button was pressed
    if (buttonBuffer == BLUE)
    {
      // if said yes, play again
      // TODO change to generate problem state
      gameState = PROBLEM_GENERATION;
    }
    else
    {
      // if said no, don't play again
      gameState = MAIN;
    }
    osSemaphoreRelease(buttonSemEMPTYHandle);
  }
}
/* USER CODE END 0 */

int main(void)
{

  /* MCU Configuration--------------------------------------------------------*/

  /* Reset of all peripherals, Initializes the Flash interface and the Systick. */
  HAL_Init();

  /* Configure the system clock */
  SystemClock_Config();

  /* Initialize all configured peripherals */
  MX_GPIO_Init();
  MX_ADC1_Init();
  MX_DAC_Init();
  MX_DFSDM1_Init();
  MX_DFSDM2_Init();
  MX_FMPI2C1_Init();
  MX_FSMC_Init();
  MX_I2S2_Init();
  MX_QUADSPI_Init();
  MX_UART10_Init();
  MX_USART6_UART_Init();
  MX_I2C2_Init();
  /* USER CODE BEGIN 2 */
  TM_RNG_Init();
  BSP_LCD_Init();
  BSP_LCD_Clear(LCD_COLOR_WHITE);
  // BSP_LCD_Clear(LCD_COLOR_WHITE);
  /* USER CODE END 2 */

  /* Init scheduler */
  osKernelInitialize();
  /* Create the mutex(es) */
  /* creation of displayMutex */
  displayMutexHandle = osMutexNew(&displayMutex_attributes);

  /* creation of ledMutex */
  ledMutexHandle = osMutexNew(&ledMutex_attributes);

  /* creation of buttonMutex */
  buttonMutexHandle = osMutexNew(&buttonMutex_attributes);

  /* Create the semaphores(s) */
  /* creation of displaySemEMPTY */
  displaySemEMPTYHandle = osSemaphoreNew(1, 1, &displaySemEMPTY_attributes);

  /* creation of displaySemFULL */
  displaySemFULLHandle = osSemaphoreNew(1, 1, &displaySemFULL_attributes);

  /* creation of buttonSemFULL */
  buttonSemFULLHandle = osSemaphoreNew(1, 1, &buttonSemFULL_attributes);

  /* creation of buttonSemEMPTY */
  buttonSemEMPTYHandle = osSemaphoreNew(1, 1, &buttonSemEMPTY_attributes);

  /* creation of ledSemFULL */
  ledSemFULLHandle = osSemaphoreNew(1, 1, &ledSemFULL_attributes);

  /* creation of ledSEMEmpty */
  ledSEMEmptyHandle = osSemaphoreNew(1, 1, &ledSEMEmpty_attributes);

  /* USER CODE BEGIN RTOS_SEMAPHORES */
  osMutexAcquire(ledSemFULLHandle, 5);
  osMutexAcquire(buttonSemFULLHandle, 5);
  osMutexAcquire(displaySemFULLHandle, 5);
  /* USER CODE END RTOS_SEMAPHORES */

  /* Create the timer(s) */
  /* creation of problemTimeout */
  problemTimeoutHandle = osTimerNew(problemTimeoutCallback, osTimerOnce, NULL, &problemTimeout_attributes);

  /* creation of dotTimer */
  dotTimerHandle = osTimerNew(dotCallback, osTimerOnce, NULL, &dotTimer_attributes);

  /* creation of dashTimer */
  dashTimerHandle = osTimerNew(dashCallback, osTimerOnce, NULL, &dashTimer_attributes);

  /* Create the thread(s) */
  /* creation of gameTask */
  gameTaskHandle = osThreadNew(gameHandler, NULL, &gameTask_attributes);

  /* creation of displayTask */
  displayTaskHandle = osThreadNew(displayHandler, NULL, &displayTask_attributes);

  /* creation of buttonTask */
  buttonTaskHandle = osThreadNew(buttonHandler, NULL, &buttonTask_attributes);

  /* creation of ledTask */
  ledTaskHandle = osThreadNew(ledHandler, NULL, &ledTask_attributes);

  /* creation of runIndicate */
  runIndicateHandle = osThreadNew(runIndicateHandler, NULL, &runIndicate_attributes);

  /* Start scheduler */
  osKernelStart();

  /* We should never get here as control is now taken by the scheduler */
  /* Infinite loop */
  while (1)
  {

  }
}

void SystemClock_Config(void)
{
  RCC_OscInitTypeDef RCC_OscInitStruct = {0};
  RCC_ClkInitTypeDef RCC_ClkInitStruct = {0};
  RCC_PeriphCLKInitTypeDef PeriphClkInitStruct = {0};

  /** Configure the main internal regulator output voltage
   */
  __HAL_RCC_PWR_CLK_ENABLE();
  __HAL_PWR_VOLTAGESCALING_CONFIG(PWR_REGULATOR_VOLTAGE_SCALE1);
  /** Initializes the RCC Oscillators according to the specified parameters
   * in the RCC_OscInitTypeDef structure.
   */
  RCC_OscInitStruct.OscillatorType = RCC_OSCILLATORTYPE_HSI | RCC_OSCILLATORTYPE_HSE;
  RCC_OscInitStruct.HSEState = RCC_HSE_BYPASS;
  RCC_OscInitStruct.HSIState = RCC_HSI_ON;
  RCC_OscInitStruct.HSICalibrationValue = RCC_HSICALIBRATION_DEFAULT;
  RCC_OscInitStruct.PLL.PLLState = RCC_PLL_ON;
  RCC_OscInitStruct.PLL.PLLSource = RCC_PLLSOURCE_HSE;
  RCC_OscInitStruct.PLL.PLLM = 15;
  RCC_OscInitStruct.PLL.PLLN = 144;
  RCC_OscInitStruct.PLL.PLLP = RCC_PLLP_DIV2;
  RCC_OscInitStruct.PLL.PLLQ = 5;
  RCC_OscInitStruct.PLL.PLLR = 2;
  if (HAL_RCC_OscConfig(&RCC_OscInitStruct) != HAL_OK)
  {
    Error_Handler();
  }
  /** Initializes the CPU, AHB and APB buses clocks
   */
  RCC_ClkInitStruct.ClockType = RCC_CLOCKTYPE_HCLK | RCC_CLOCKTYPE_SYSCLK | RCC_CLOCKTYPE_PCLK1 | RCC_CLOCKTYPE_PCLK2;
  RCC_ClkInitStruct.SYSCLKSource = RCC_SYSCLKSOURCE_HSI;
  RCC_ClkInitStruct.AHBCLKDivider = RCC_SYSCLK_DIV1;
  RCC_ClkInitStruct.APB1CLKDivider = RCC_HCLK_DIV1;
  RCC_ClkInitStruct.APB2CLKDivider = RCC_HCLK_DIV1;

  if (HAL_RCC_ClockConfig(&RCC_ClkInitStruct, FLASH_LATENCY_0) != HAL_OK)
  {
    Error_Handler();
  }
  PeriphClkInitStruct.PeriphClockSelection = RCC_PERIPHCLK_I2S_APB1 | RCC_PERIPHCLK_DFSDM1 | RCC_PERIPHCLK_CLK48 | RCC_PERIPHCLK_FMPI2C1;
  PeriphClkInitStruct.PLLI2S.PLLI2SN = 50;
  PeriphClkInitStruct.PLLI2S.PLLI2SM = 12;
  PeriphClkInitStruct.PLLI2S.PLLI2SR = 2;
  PeriphClkInitStruct.PLLI2S.PLLI2SQ = 2;
  PeriphClkInitStruct.Clk48ClockSelection = RCC_CLK48CLKSOURCE_PLLQ;
  PeriphClkInitStruct.Dfsdm1ClockSelection = RCC_DFSDM1CLKSOURCE_APB2;
  PeriphClkInitStruct.PLLI2SSelection = RCC_PLLI2SCLKSOURCE_PLLSRC;
  PeriphClkInitStruct.I2sApb1ClockSelection = RCC_I2SAPB1CLKSOURCE_PLLI2S;
  PeriphClkInitStruct.Fmpi2c1ClockSelection = RCC_FMPI2C1CLKSOURCE_APB;
  if (HAL_RCCEx_PeriphCLKConfig(&PeriphClkInitStruct) != HAL_OK)
  {
    Error_Handler();
  }
}

static void MX_ADC1_Init(void)
{

  ADC_ChannelConfTypeDef sConfig = {0};

  /** Configure the global features of the ADC (Clock, Resolution, Data Alignment and number of conversion)
   */
  hadc1.Instance = ADC1;
  hadc1.Init.ClockPrescaler = ADC_CLOCK_SYNC_PCLK_DIV2;
  hadc1.Init.Resolution = ADC_RESOLUTION_12B;
  hadc1.Init.ScanConvMode = DISABLE;
  hadc1.Init.ContinuousConvMode = DISABLE;
  hadc1.Init.DiscontinuousConvMode = DISABLE;
  hadc1.Init.ExternalTrigConvEdge = ADC_EXTERNALTRIGCONVEDGE_NONE;
  hadc1.Init.ExternalTrigConv = ADC_SOFTWARE_START;
  hadc1.Init.DataAlign = ADC_DATAALIGN_RIGHT;
  hadc1.Init.NbrOfConversion = 1;
  hadc1.Init.DMAContinuousRequests = DISABLE;
  hadc1.Init.EOCSelection = ADC_EOC_SINGLE_CONV;
  if (HAL_ADC_Init(&hadc1) != HAL_OK)
  {
    Error_Handler();
  }
  /** Configure for the selected ADC regular channel its corresponding rank in the sequencer and its sample time.
   */
  sConfig.Channel = ADC_CHANNEL_10;
  sConfig.Rank = 1;
  sConfig.SamplingTime = ADC_SAMPLETIME_3CYCLES;
  if (HAL_ADC_ConfigChannel(&hadc1, &sConfig) != HAL_OK)
  {
    Error_Handler();
  }
}

static void MX_DAC_Init(void)
{

  DAC_ChannelConfTypeDef sConfig = {0};

  /** DAC Initialization
   */
  hdac.Instance = DAC;
  if (HAL_DAC_Init(&hdac) != HAL_OK)
  {
    Error_Handler();
  }
  /** DAC channel OUT1 config
   */
  sConfig.DAC_Trigger = DAC_TRIGGER_NONE;
  sConfig.DAC_OutputBuffer = DAC_OUTPUTBUFFER_ENABLE;
  if (HAL_DAC_ConfigChannel(&hdac, &sConfig, DAC_CHANNEL_1) != HAL_OK)
  {
    Error_Handler();
  }
}

static void MX_DFSDM1_Init(void)
{

  hdfsdm1_channel1.Instance = DFSDM1_Channel1;
  hdfsdm1_channel1.Init.OutputClock.Activation = ENABLE;
  hdfsdm1_channel1.Init.OutputClock.Selection = DFSDM_CHANNEL_OUTPUT_CLOCK_SYSTEM;
  hdfsdm1_channel1.Init.OutputClock.Divider = 2;
  hdfsdm1_channel1.Init.Input.Multiplexer = DFSDM_CHANNEL_EXTERNAL_INPUTS;
  hdfsdm1_channel1.Init.Input.DataPacking = DFSDM_CHANNEL_STANDARD_MODE;
  hdfsdm1_channel1.Init.Input.Pins = DFSDM_CHANNEL_SAME_CHANNEL_PINS;
  hdfsdm1_channel1.Init.SerialInterface.Type = DFSDM_CHANNEL_MANCHESTER_RISING;
  hdfsdm1_channel1.Init.SerialInterface.SpiClock = DFSDM_CHANNEL_SPI_CLOCK_EXTERNAL;
  hdfsdm1_channel1.Init.Awd.FilterOrder = DFSDM_CHANNEL_FASTSINC_ORDER;
  hdfsdm1_channel1.Init.Awd.Oversampling = 1;
  hdfsdm1_channel1.Init.Offset = 0;
  hdfsdm1_channel1.Init.RightBitShift = 0x00;
  if (HAL_DFSDM_ChannelInit(&hdfsdm1_channel1) != HAL_OK)
  {
    Error_Handler();
  }
}

static void MX_DFSDM2_Init(void)
{

  hdfsdm2_channel1.Instance = DFSDM2_Channel1;
  hdfsdm2_channel1.Init.OutputClock.Activation = ENABLE;
  hdfsdm2_channel1.Init.OutputClock.Selection = DFSDM_CHANNEL_OUTPUT_CLOCK_SYSTEM;
  hdfsdm2_channel1.Init.OutputClock.Divider = 2;
  hdfsdm2_channel1.Init.Input.Multiplexer = DFSDM_CHANNEL_EXTERNAL_INPUTS;
  hdfsdm2_channel1.Init.Input.DataPacking = DFSDM_CHANNEL_STANDARD_MODE;
  hdfsdm2_channel1.Init.Input.Pins = DFSDM_CHANNEL_SAME_CHANNEL_PINS;
  hdfsdm2_channel1.Init.SerialInterface.Type = DFSDM_CHANNEL_MANCHESTER_RISING;
  hdfsdm2_channel1.Init.SerialInterface.SpiClock = DFSDM_CHANNEL_SPI_CLOCK_EXTERNAL;
  hdfsdm2_channel1.Init.Awd.FilterOrder = DFSDM_CHANNEL_FASTSINC_ORDER;
  hdfsdm2_channel1.Init.Awd.Oversampling = 1;
  hdfsdm2_channel1.Init.Offset = 0;
  hdfsdm2_channel1.Init.RightBitShift = 0x00;
  if (HAL_DFSDM_ChannelInit(&hdfsdm2_channel1) != HAL_OK)
  {
    Error_Handler();
  }
  hdfsdm2_channel7.Instance = DFSDM2_Channel7;
  hdfsdm2_channel7.Init.OutputClock.Activation = ENABLE;
  hdfsdm2_channel7.Init.OutputClock.Selection = DFSDM_CHANNEL_OUTPUT_CLOCK_SYSTEM;
  hdfsdm2_channel7.Init.OutputClock.Divider = 2;
  hdfsdm2_channel7.Init.Input.Multiplexer = DFSDM_CHANNEL_EXTERNAL_INPUTS;
  hdfsdm2_channel7.Init.Input.DataPacking = DFSDM_CHANNEL_STANDARD_MODE;
  hdfsdm2_channel7.Init.Input.Pins = DFSDM_CHANNEL_SAME_CHANNEL_PINS;
  hdfsdm2_channel7.Init.SerialInterface.Type = DFSDM_CHANNEL_MANCHESTER_RISING;
  hdfsdm2_channel7.Init.SerialInterface.SpiClock = DFSDM_CHANNEL_SPI_CLOCK_EXTERNAL;
  hdfsdm2_channel7.Init.Awd.FilterOrder = DFSDM_CHANNEL_FASTSINC_ORDER;
  hdfsdm2_channel7.Init.Awd.Oversampling = 1;
  hdfsdm2_channel7.Init.Offset = 0;
  hdfsdm2_channel7.Init.RightBitShift = 0x00;
  if (HAL_DFSDM_ChannelInit(&hdfsdm2_channel7) != HAL_OK)
  {
    Error_Handler();
  }
}

static void MX_FMPI2C1_Init(void)
{

  hfmpi2c1.Instance = FMPI2C1;
  hfmpi2c1.Init.Timing = 0x00303D5B;
  hfmpi2c1.Init.OwnAddress1 = 0;
  hfmpi2c1.Init.AddressingMode = FMPI2C_ADDRESSINGMODE_7BIT;
  hfmpi2c1.Init.DualAddressMode = FMPI2C_DUALADDRESS_DISABLE;
  hfmpi2c1.Init.OwnAddress2 = 0;
  hfmpi2c1.Init.OwnAddress2Masks = FMPI2C_OA2_NOMASK;
  hfmpi2c1.Init.GeneralCallMode = FMPI2C_GENERALCALL_DISABLE;
  hfmpi2c1.Init.NoStretchMode = FMPI2C_NOSTRETCH_DISABLE;
  if (HAL_FMPI2C_Init(&hfmpi2c1) != HAL_OK)
  {
    Error_Handler();
  }
  /** Configure Analogue filter
   */
  if (HAL_FMPI2CEx_ConfigAnalogFilter(&hfmpi2c1, FMPI2C_ANALOGFILTER_ENABLE) != HAL_OK)
  {
    Error_Handler();
  }
}

static void MX_I2C2_Init(void)
{

  hi2c2.Instance = I2C2;
  hi2c2.Init.ClockSpeed = 100000;
  hi2c2.Init.DutyCycle = I2C_DUTYCYCLE_2;
  hi2c2.Init.OwnAddress1 = 0;
  hi2c2.Init.AddressingMode = I2C_ADDRESSINGMODE_7BIT;
  hi2c2.Init.DualAddressMode = I2C_DUALADDRESS_DISABLE;
  hi2c2.Init.OwnAddress2 = 0;
  hi2c2.Init.GeneralCallMode = I2C_GENERALCALL_DISABLE;
  hi2c2.Init.NoStretchMode = I2C_NOSTRETCH_DISABLE;
  if (HAL_I2C_Init(&hi2c2) != HAL_OK)
  {
    Error_Handler();
  }
}

static void MX_I2S2_Init(void)
{

  hi2s2.Instance = SPI2;
  hi2s2.Init.Mode = I2S_MODE_MASTER_TX;
  hi2s2.Init.Standard = I2S_STANDARD_PHILIPS;
  hi2s2.Init.DataFormat = I2S_DATAFORMAT_16B;
  hi2s2.Init.MCLKOutput = I2S_MCLKOUTPUT_ENABLE;
  hi2s2.Init.AudioFreq = I2S_AUDIOFREQ_8K;
  hi2s2.Init.CPOL = I2S_CPOL_LOW;
  hi2s2.Init.ClockSource = I2S_CLOCK_PLL;
  hi2s2.Init.FullDuplexMode = I2S_FULLDUPLEXMODE_ENABLE;
  if (HAL_I2S_Init(&hi2s2) != HAL_OK)
  {
    Error_Handler();
  }
}

static void MX_QUADSPI_Init(void)
{

  /* QUADSPI parameter configuration*/
  hqspi.Instance = QUADSPI;
  hqspi.Init.ClockPrescaler = 255;
  hqspi.Init.FifoThreshold = 1;
  hqspi.Init.SampleShifting = QSPI_SAMPLE_SHIFTING_NONE;
  hqspi.Init.FlashSize = 1;
  hqspi.Init.ChipSelectHighTime = QSPI_CS_HIGH_TIME_1_CYCLE;
  hqspi.Init.ClockMode = QSPI_CLOCK_MODE_0;
  hqspi.Init.FlashID = QSPI_FLASH_ID_1;
  hqspi.Init.DualFlash = QSPI_DUALFLASH_DISABLE;
  if (HAL_QSPI_Init(&hqspi) != HAL_OK)
  {
    Error_Handler();
  }
}

static void MX_UART10_Init(void)
{

  huart10.Instance = UART10;
  huart10.Init.BaudRate = 115200;
  huart10.Init.WordLength = UART_WORDLENGTH_8B;
  huart10.Init.StopBits = UART_STOPBITS_1;
  huart10.Init.Parity = UART_PARITY_NONE;
  huart10.Init.Mode = UART_MODE_TX_RX;
  huart10.Init.HwFlowCtl = UART_HWCONTROL_NONE;
  huart10.Init.OverSampling = UART_OVERSAMPLING_16;
  if (HAL_UART_Init(&huart10) != HAL_OK)
  {
    Error_Handler();
  }
}

static void MX_USART6_UART_Init(void)
{

  huart6.Instance = USART6;
  huart6.Init.BaudRate = 115200;
  huart6.Init.WordLength = UART_WORDLENGTH_8B;
  huart6.Init.StopBits = UART_STOPBITS_1;
  huart6.Init.Parity = UART_PARITY_NONE;
  huart6.Init.Mode = UART_MODE_TX_RX;
  huart6.Init.HwFlowCtl = UART_HWCONTROL_NONE;
  huart6.Init.OverSampling = UART_OVERSAMPLING_16;
  if (HAL_UART_Init(&huart6) != HAL_OK)
  {
    Error_Handler();
  }
}

static void MX_GPIO_Init(void)
{
  GPIO_InitTypeDef GPIO_InitStruct = {0};

  /* GPIO Ports Clock Enable */
  __HAL_RCC_GPIOE_CLK_ENABLE();
  __HAL_RCC_GPIOC_CLK_ENABLE();
  __HAL_RCC_GPIOF_CLK_ENABLE();
  __HAL_RCC_GPIOH_CLK_ENABLE();
  __HAL_RCC_GPIOA_CLK_ENABLE();
  __HAL_RCC_GPIOB_CLK_ENABLE();
  __HAL_RCC_GPIOG_CLK_ENABLE();
  __HAL_RCC_GPIOD_CLK_ENABLE();

  /*Configure GPIO pin Output Level */
  HAL_GPIO_WritePin(GPIOE, GPIO_PIN_3 | GPIO_PIN_4 | GPIO_PIN_5, GPIO_PIN_RESET);

  /*Configure GPIO pin Output Level */
  HAL_GPIO_WritePin(GPIOC, GPIO_PIN_5, GPIO_PIN_RESET);

  /*Configure GPIO pin Output Level */
  HAL_GPIO_WritePin(GPIOB, GPIO_PIN_13 | GPIO_PIN_14 | GPIO_PIN_15, GPIO_PIN_RESET);

  /*Configure GPIO pin Output Level */
  HAL_GPIO_WritePin(GPIOG, GPIO_PIN_8, GPIO_PIN_RESET);

  /*Configure GPIO pins : PE3 PE4 PE5 */
  GPIO_InitStruct.Pin = GPIO_PIN_3 | GPIO_PIN_4 | GPIO_PIN_5;
  GPIO_InitStruct.Mode = GPIO_MODE_OUTPUT_PP;
  GPIO_InitStruct.Pull = GPIO_NOPULL;
  GPIO_InitStruct.Speed = GPIO_SPEED_FREQ_LOW;
  HAL_GPIO_Init(GPIOE, &GPIO_InitStruct);

  /*Configure GPIO pin : PE6 */
  GPIO_InitStruct.Pin = GPIO_PIN_6;
  GPIO_InitStruct.Mode = GPIO_MODE_AF_PP;
  GPIO_InitStruct.Pull = GPIO_NOPULL;
  GPIO_InitStruct.Speed = GPIO_SPEED_FREQ_LOW;
  GPIO_InitStruct.Alternate = GPIO_AF3_TIM9;
  HAL_GPIO_Init(GPIOE, &GPIO_InitStruct);

  /*Configure GPIO pins : PF6 PF7 PF10 */
  GPIO_InitStruct.Pin = GPIO_PIN_6 | GPIO_PIN_7 | GPIO_PIN_10;
  GPIO_InitStruct.Mode = GPIO_MODE_INPUT;
  GPIO_InitStruct.Pull = GPIO_NOPULL;
  HAL_GPIO_Init(GPIOF, &GPIO_InitStruct);

  /*Configure GPIO pin : PC1 */
  GPIO_InitStruct.Pin = GPIO_PIN_1;
  GPIO_InitStruct.Mode = GPIO_MODE_IT_RISING;
  GPIO_InitStruct.Pull = GPIO_NOPULL;
  HAL_GPIO_Init(GPIOC, &GPIO_InitStruct);

  /*Configure GPIO pin : PA0 */
  GPIO_InitStruct.Pin = GPIO_PIN_0;
  GPIO_InitStruct.Mode = GPIO_MODE_INPUT;
  GPIO_InitStruct.Pull = GPIO_NOPULL;
  HAL_GPIO_Init(GPIOA, &GPIO_InitStruct);

  /*Configure GPIO pin : PA6 */
  GPIO_InitStruct.Pin = GPIO_PIN_6;
  GPIO_InitStruct.Mode = GPIO_MODE_AF_PP;
  GPIO_InitStruct.Pull = GPIO_NOPULL;
  GPIO_InitStruct.Speed = GPIO_SPEED_FREQ_VERY_HIGH;
  GPIO_InitStruct.Alternate = GPIO_AF12_SDIO;
  HAL_GPIO_Init(GPIOA, &GPIO_InitStruct);

  /*Configure GPIO pin : PC5 */
  GPIO_InitStruct.Pin = GPIO_PIN_5;
  GPIO_InitStruct.Mode = GPIO_MODE_OUTPUT_PP;
  GPIO_InitStruct.Pull = GPIO_NOPULL;
  GPIO_InitStruct.Speed = GPIO_SPEED_FREQ_LOW;
  HAL_GPIO_Init(GPIOC, &GPIO_InitStruct);

  /*Configure GPIO pin : PB0 */
  GPIO_InitStruct.Pin = GPIO_PIN_0;
  GPIO_InitStruct.Mode = GPIO_MODE_AF_PP;
  GPIO_InitStruct.Pull = GPIO_NOPULL;
  GPIO_InitStruct.Speed = GPIO_SPEED_FREQ_LOW;
  GPIO_InitStruct.Alternate = GPIO_AF2_TIM3;
  HAL_GPIO_Init(GPIOB, &GPIO_InitStruct);

  /*Configure GPIO pin : PF11 */
  GPIO_InitStruct.Pin = GPIO_PIN_11;
  GPIO_InitStruct.Mode = GPIO_MODE_IT_RISING;
  GPIO_InitStruct.Pull = GPIO_NOPULL;
  HAL_GPIO_Init(GPIOF, &GPIO_InitStruct);

  /*Configure GPIO pin : PB12 */
  GPIO_InitStruct.Pin = GPIO_PIN_12;
  GPIO_InitStruct.Mode = GPIO_MODE_AF_PP;
  GPIO_InitStruct.Pull = GPIO_NOPULL;
  GPIO_InitStruct.Speed = GPIO_SPEED_FREQ_VERY_HIGH;
  GPIO_InitStruct.Alternate = GPIO_AF7_SPI3;
  HAL_GPIO_Init(GPIOB, &GPIO_InitStruct);

  /*Configure GPIO pins : PB13 PB14 PB15 */
  GPIO_InitStruct.Pin = GPIO_PIN_13 | GPIO_PIN_14 | GPIO_PIN_15;
  GPIO_InitStruct.Mode = GPIO_MODE_OUTPUT_PP;
  GPIO_InitStruct.Pull = GPIO_NOPULL;
  GPIO_InitStruct.Speed = GPIO_SPEED_FREQ_LOW;
  HAL_GPIO_Init(GPIOB, &GPIO_InitStruct);

  /*Configure GPIO pin : PG8 */
  GPIO_InitStruct.Pin = GPIO_PIN_8;
  GPIO_InitStruct.Mode = GPIO_MODE_OUTPUT_PP;
  GPIO_InitStruct.Pull = GPIO_NOPULL;
  GPIO_InitStruct.Speed = GPIO_SPEED_FREQ_LOW;
  HAL_GPIO_Init(GPIOG, &GPIO_InitStruct);

  /*Configure GPIO pins : PC8 PC9 PC10 PC11
                           PC12 */
  GPIO_InitStruct.Pin = GPIO_PIN_8 | GPIO_PIN_9 | GPIO_PIN_10 | GPIO_PIN_11 | GPIO_PIN_12;
  GPIO_InitStruct.Mode = GPIO_MODE_AF_PP;
  GPIO_InitStruct.Pull = GPIO_NOPULL;
  GPIO_InitStruct.Speed = GPIO_SPEED_FREQ_VERY_HIGH;
  GPIO_InitStruct.Alternate = GPIO_AF12_SDIO;
  HAL_GPIO_Init(GPIOC, &GPIO_InitStruct);

  /*Configure GPIO pin : PA15 */
  GPIO_InitStruct.Pin = GPIO_PIN_15;
  GPIO_InitStruct.Mode = GPIO_MODE_AF_PP;
  GPIO_InitStruct.Pull = GPIO_NOPULL;
  GPIO_InitStruct.Speed = GPIO_SPEED_FREQ_LOW;
  GPIO_InitStruct.Alternate = GPIO_AF1_TIM2;
  HAL_GPIO_Init(GPIOA, &GPIO_InitStruct);

  /*Configure GPIO pin : PG13 */
  GPIO_InitStruct.Pin = GPIO_PIN_13;
  GPIO_InitStruct.Mode = GPIO_MODE_INPUT;
  GPIO_InitStruct.Pull = GPIO_NOPULL;
  HAL_GPIO_Init(GPIOG, &GPIO_InitStruct);

  /*Configure GPIO pin : PG15 */
  GPIO_InitStruct.Pin = GPIO_PIN_15;
  GPIO_InitStruct.Mode = GPIO_MODE_IT_RISING;
  GPIO_InitStruct.Pull = GPIO_NOPULL;
  HAL_GPIO_Init(GPIOG, &GPIO_InitStruct);

  /*Configure GPIO pins : PB4 PB5 */
  GPIO_InitStruct.Pin = GPIO_PIN_4 | GPIO_PIN_5;
  GPIO_InitStruct.Mode = GPIO_MODE_AF_PP;
  GPIO_InitStruct.Pull = GPIO_NOPULL;
  GPIO_InitStruct.Speed = GPIO_SPEED_FREQ_VERY_HIGH;
  GPIO_InitStruct.Alternate = GPIO_AF6_SPI3;
  HAL_GPIO_Init(GPIOB, &GPIO_InitStruct);

  /*Configure GPIO pin : PB8 */
  GPIO_InitStruct.Pin = GPIO_PIN_8;
  GPIO_InitStruct.Mode = GPIO_MODE_AF_PP;
  GPIO_InitStruct.Pull = GPIO_NOPULL;
  GPIO_InitStruct.Speed = GPIO_SPEED_FREQ_LOW;
  GPIO_InitStruct.Alternate = GPIO_AF2_TIM4;
  HAL_GPIO_Init(GPIOB, &GPIO_InitStruct);
}

/* FSMC initialization function */
static void MX_FSMC_Init(void)
{

  FSMC_NORSRAM_TimingTypeDef Timing = {0};

  /** Perform the SRAM1 memory initialization sequence
   */
  hsram1.Instance = FSMC_NORSRAM_DEVICE;
  hsram1.Extended = FSMC_NORSRAM_EXTENDED_DEVICE;
  /* hsram1.Init */
  hsram1.Init.NSBank = FSMC_NORSRAM_BANK1;
  hsram1.Init.DataAddressMux = FSMC_DATA_ADDRESS_MUX_DISABLE;
  hsram1.Init.MemoryType = FSMC_MEMORY_TYPE_SRAM;
  hsram1.Init.MemoryDataWidth = FSMC_NORSRAM_MEM_BUS_WIDTH_16;
  hsram1.Init.BurstAccessMode = FSMC_BURST_ACCESS_MODE_DISABLE;
  hsram1.Init.WaitSignalPolarity = FSMC_WAIT_SIGNAL_POLARITY_LOW;
  hsram1.Init.WaitSignalActive = FSMC_WAIT_TIMING_BEFORE_WS;
  hsram1.Init.WriteOperation = FSMC_WRITE_OPERATION_ENABLE;
  hsram1.Init.WaitSignal = FSMC_WAIT_SIGNAL_DISABLE;
  hsram1.Init.ExtendedMode = FSMC_EXTENDED_MODE_DISABLE;
  hsram1.Init.AsynchronousWait = FSMC_ASYNCHRONOUS_WAIT_DISABLE;
  hsram1.Init.WriteBurst = FSMC_WRITE_BURST_DISABLE;
  hsram1.Init.ContinuousClock = FSMC_CONTINUOUS_CLOCK_SYNC_ONLY;
  hsram1.Init.WriteFifo = FSMC_WRITE_FIFO_ENABLE;
  hsram1.Init.PageSize = FSMC_PAGE_SIZE_NONE;
  /* Timing */
  Timing.AddressSetupTime = 15;
  Timing.AddressHoldTime = 15;
  Timing.DataSetupTime = 255;
  Timing.BusTurnAroundDuration = 15;
  Timing.CLKDivision = 16;
  Timing.DataLatency = 17;
  Timing.AccessMode = FSMC_ACCESS_MODE_A;
  /* ExtTiming */

  if (HAL_SRAM_Init(&hsram1, &Timing, NULL) != HAL_OK)
  {
    Error_Handler();
  }

  /** Perform the SRAM2 memory initialization sequence
   */
  hsram2.Instance = FSMC_NORSRAM_DEVICE;
  hsram2.Extended = FSMC_NORSRAM_EXTENDED_DEVICE;
  /* hsram2.Init */
  hsram2.Init.NSBank = FSMC_NORSRAM_BANK3;
  hsram2.Init.DataAddressMux = FSMC_DATA_ADDRESS_MUX_DISABLE;
  hsram2.Init.MemoryType = FSMC_MEMORY_TYPE_SRAM;
  hsram2.Init.MemoryDataWidth = FSMC_NORSRAM_MEM_BUS_WIDTH_16;
  hsram2.Init.BurstAccessMode = FSMC_BURST_ACCESS_MODE_DISABLE;
  hsram2.Init.WaitSignalPolarity = FSMC_WAIT_SIGNAL_POLARITY_LOW;
  hsram2.Init.WaitSignalActive = FSMC_WAIT_TIMING_BEFORE_WS;
  hsram2.Init.WriteOperation = FSMC_WRITE_OPERATION_ENABLE;
  hsram2.Init.WaitSignal = FSMC_WAIT_SIGNAL_DISABLE;
  hsram2.Init.ExtendedMode = FSMC_EXTENDED_MODE_DISABLE;
  hsram2.Init.AsynchronousWait = FSMC_ASYNCHRONOUS_WAIT_DISABLE;
  hsram2.Init.WriteBurst = FSMC_WRITE_BURST_DISABLE;
  hsram2.Init.ContinuousClock = FSMC_CONTINUOUS_CLOCK_SYNC_ONLY;
  hsram2.Init.WriteFifo = FSMC_WRITE_FIFO_ENABLE;
  hsram2.Init.PageSize = FSMC_PAGE_SIZE_NONE;
  /* Timing */
  Timing.AddressSetupTime = 15;
  Timing.AddressHoldTime = 15;
  Timing.DataSetupTime = 255;
  Timing.BusTurnAroundDuration = 15;
  Timing.CLKDivision = 16;
  Timing.DataLatency = 17;
  Timing.AccessMode = FSMC_ACCESS_MODE_A;
  /* ExtTiming */

  if (HAL_SRAM_Init(&hsram2, &Timing, NULL) != HAL_OK)
  {
    Error_Handler();
  }

}

void gameHandler(void *argument)
{
  /* init code for USB_HOST */
  MX_USB_HOST_Init();
  /* USER CODE BEGIN 5 */
  /* Infinite loop */
  for (;;)
  {
    switch (gameState)
    {
    case MAIN:
      gameMain();
      break;
    case PROBLEM_GENERATION:
      gameProblemGeneration();
      break;
    case PROBLEM:
      gameProblem();
      break;
    case END:
      gameEnd();
      break;
    }
    osDelay(1);
  }
  /* USER CODE END 5 */
}

void displayHandler(void *argument)
{
  /* USER CODE BEGIN displayHandler */
  /* Infinite loop */
  for (;;)
  {
    int PAD = 10;
    int CHAR_WIDTH = 5;
    int CHAR_HEIGHT = 5;
    int RECT_HEIGHT = 30;
    int RECT_WIDTH = RECT_HEIGHT;

    osSemaphoreAcquire(displaySemFULLHandle, osWaitForever);
    if (gameState == MAIN)
    {
      // Display in Main game state
      BSP_LCD_Clear(LCD_COLOR_WHITE);
      u_int8_t *welcomeMsg1 = "Welcome to the";
      u_int8_t *welcomeMsg2 = "Morse Code Tutor!";
      u_int8_t *letterProbsMsg = "Letter Problems";
      u_int8_t *wordProbsMsg = "Word Problems";
      BSP_LCD_SetTextColor(LCD_COLOR_BLACK);
      BSP_LCD_DisplayStringAt(0, 300, welcomeMsg1, CENTER_MODE);
      BSP_LCD_DisplayStringAt(0, 300 + CHAR_HEIGHT + PAD, welcomeMsg2, CENTER_MODE);
      BSP_LCD_SetTextColor(BUTTON_COLORS[0]);
      BSP_LCD_DisplayStringAt(0, 300 + 2 * (CHAR_HEIGHT + PAD), letterProbsMsg, CENTER_MODE);
      BSP_LCD_SetTextColor(BUTTON_COLORS[1]);
      BSP_LCD_DisplayStringAt(0, 300 + 3 * (CHAR_HEIGHT + PAD), wordProbsMsg, CENTER_MODE);
      BSP_LCD_SetTextColor(LCD_COLOR_BLACK);
    }
    else if (gameState == PROBLEM)
    {
      // Clear LCD
      BSP_LCD_Clear(LCD_COLOR_WHITE);
      if (propblemState == WORD)
      {
        // 20 is maximum number of characters in the words we're using
        RECT_WIDTH = RECT_HEIGHT + 20 * CHAR_WIDTH;
      }
      else
      {
        RECT_WIDTH = RECT_HEIGHT;
      }

      // Display user button choices
      for (int i = 0; i < 4; i++)
      {
        int y = PAD + (RECT_HEIGHT + PAD) * i;
        // display square/rect of button color
        BSP_LCD_SetTextColor(BUTTON_COLORS[i]);
        BSP_LCD_FillRect(PAD, y, RECT_WIDTH, RECT_HEIGHT);

        // display text of corresponding letter option on top of colored square
        if (BUTTON_COLORS[i] == LCD_COLOR_YELLOW || BUTTON_COLORS[i] == LCD_COLOR_GREEN)
        {
          BSP_LCD_SetTextColor(LCD_COLOR_BLACK);
        }
        else
        {
          BSP_LCD_SetTextColor(LCD_COLOR_WHITE);
        }
        int charX = PAD + (RECT_HEIGHT - CHAR_WIDTH) / 2;
        int charY = y + (RECT_HEIGHT - CHAR_HEIGHT) / 2;
        BSP_LCD_SetBackColor(BUTTON_COLORS[i]);
        BSP_LCD_DisplayStringAt(charX, charY, choices[i], LEFT_MODE);
      }
      BSP_LCD_SetBackColor(LCD_COLOR_WHITE);
    }
    else if (gameState == END)
    {
      // Display in End game state: Correct/Incorrect answer
      int chosenY = PAD + (RECT_HEIGHT + PAD) * chosenChoice + RECT_HEIGHT / 2 - CHAR_HEIGHT;
      int correctY = PAD + (RECT_HEIGHT + PAD) * correctChoice + RECT_HEIGHT / 2 - CHAR_HEIGHT;
      u_int8_t *correctMsg = "Correct!";
      u_int8_t *scoreMsg = "score:   ";
      u_int8_t *totalAttemptsMsg = "Attempts:   ";

      char userScoreMessage[4];
      char problemsDoneMessage[4];
      intToString(userScore, &userScoreMessage[0], 4);
      intToString(problemsDone, &problemsDoneMessage[0], 4);

      BSP_LCD_DisplayStringAt(10, 210, scoreMsg, RIGHT_MODE);            // align with bottom left of screen
      BSP_LCD_DisplayStringAt(10, 210, userScoreMessage, RIGHT_MODE);    // just below previous string
      BSP_LCD_DisplayStringAt(10, 220, totalAttemptsMsg, RIGHT_MODE);    // just below previous string
      BSP_LCD_DisplayStringAt(10, 220, problemsDoneMessage, RIGHT_MODE); // just below previous string
      if (chosenChoice != correctChoice)
      {
        // Display answer was incorrect
        BSP_LCD_SetTextColor(LCD_COLOR_RED);
        u_int8_t *incorrectChar = "X";
        BSP_LCD_DisplayStringAt(PAD * 2 + RECT_WIDTH, chosenY, incorrectChar, LEFT_MODE);
        correctMsg = "<-";
      }
      // Indicate correct answer
      BSP_LCD_SetTextColor(LCD_COLOR_GREEN);
      BSP_LCD_DisplayStringAt(PAD * 2 + RECT_WIDTH, correctY, correctMsg, LEFT_MODE);

      // Prompt play-again
      int X = 50;
      int Y = PAD * 5 + RECT_HEIGHT * 4;
      u_int8_t *playAgainMsg = "Play Again?";
      BSP_LCD_SetTextColor(LCD_COLOR_BLACK);
      BSP_LCD_DisplayStringAt(0, Y, playAgainMsg, CENTER_MODE);

      u_int8_t *yesMsg = "Yes";
      BSP_LCD_SetTextColor(BUTTON_COLORS[0]);
      BSP_LCD_DisplayStringAt(-PAD / 2 - CHAR_WIDTH * 3, Y + PAD + CHAR_HEIGHT, yesMsg, CENTER_MODE);

      u_int8_t *noMsg = "No";
      BSP_LCD_SetTextColor(BUTTON_COLORS[1]);
      BSP_LCD_DisplayStringAt(PAD / 2, Y + PAD + CHAR_HEIGHT, noMsg, CENTER_MODE);
    }
    osSemaphoreRelease(displaySemEMPTYHandle);
    osDelay(1);
  }
  /* USER CODE END displayHandler */
}

void buttonHandler(void *argument)
{
  /* USER CODE BEGIN buttonHandler */
  osStatus_t status;
  /* Infinite loop */
  for (;;)
  {
    status = osSemaphoreAcquire(buttonSemEMPTYHandle, osWaitForever);
    status = osMutexAcquire(buttonMutexHandle, osWaitForever);
    buttonBuffer = BUTTON_NONE;
    bool buttonPressed = false;

    while (!buttonPressed)
    {

      int button1Count = 0;
      int button2Count = 0;
      int button3Count = 0;
      int button4Count = 0;

      for (int i = 0; i < 10; i++)
      {
        if (HAL_GPIO_ReadPin(GPIOF, GPIO_PIN_10))
        {
          button1Count += 1;
        }
        if (HAL_GPIO_ReadPin(GPIOF, GPIO_PIN_7))
        {
          button2Count += 1;
        }
        if (HAL_GPIO_ReadPin(GPIOF, GPIO_PIN_6))
        {
          button3Count += 1;
        }
        if (HAL_GPIO_ReadPin(GPIOG, GPIO_PIN_13))
        {
          button4Count += 1;
        }
        osDelay(10);
      }

      if (button1Count > 5)
      {
        buttonBuffer = RED;
        buttonPressed = true;
      }
      else if (button2Count > 5)
      {
        buttonBuffer = GREEN;
        buttonPressed = true;
      }
      else if (button3Count > 5)
      {
        buttonBuffer = BLUE;
        buttonPressed = true;
      }
      else if (button4Count > 5)
      {
        buttonBuffer = YELLOW;
        buttonPressed = true;
      }
    }

    status = osMutexRelease(buttonMutexHandle);
    status = osSemaphoreRelease(buttonSemFULLHandle);
  }
  /* USER CODE END buttonHandler */
}

void ledHandler(void *argument)
{
  /* USER CODE BEGIN ledHandler */

  ledTaskNotify = xTaskGetCurrentTaskHandle();
  /* Infinite loop */
  for (;;)
  {
    osSemaphoreAcquire(ledSemFULLHandle, osWaitForever);
    if (ledBuffer == DOT)
    {
      HAL_GPIO_WritePin(GPIOC, GPIO_PIN_5, SET);
      osTimerStart(dotTimerHandle, 500);
    }
    else if (ledBuffer == DASH)
    {
      HAL_GPIO_WritePin(GPIOC, GPIO_PIN_5, SET);
      osTimerStart(dashTimerHandle, 1000);
    }

    const TickType_t xMaxBlockTime = portMAX_DELAY;

    /* Wait to be notified that the transmission is complete.  Note
      the first parameter is pdTRUE, which has the effect of clearing
      the task's notification value back to 0, making the notification
      value act like a binary (rather than a counting) semaphore.  */
    uint32_t ulNotificationValue = ulTaskNotifyTake(pdTRUE, xMaxBlockTime);

    if (ulNotificationValue == 1)
    {
      HAL_GPIO_WritePin(GPIOC, GPIO_PIN_5, RESET);
      osDelay(500);
    }

    osSemaphoreRelease(ledSEMEmptyHandle);
  }
  /* USER CODE END ledHandler */
}

void runIndicateHandler(void *argument)
{
  /* USER CODE BEGIN runIndicateHandler */
#ifdef DEBUG
  /* Infinite loop */
  for (;;)
  {
    HAL_GPIO_TogglePin(GPIOE, GPIO_PIN_3);
    osDelay(1000);
  }
#else
  for (;;)
  {
    osDelay(osWaitForever);
  }
#endif

  /* USER CODE END runIndicateHandler */
}

/* problemTimeoutCallback function */
void problemTimeoutCallback(void *argument)
{
  /* USER CODE BEGIN problemTimeoutCallback */
  osDelay(2000);
  /* USER CODE END problemTimeoutCallback */
}

/* dotCallback function */
void dotCallback(void *argument)
{
  /* USER CODE BEGIN dotCallback */
  // Notify LED
  BaseType_t xHigherPriorityTaskWoken = pdFALSE;

  vTaskNotifyGiveFromISR(ledTaskNotify, &xHigherPriorityTaskWoken);
  portYIELD_FROM_ISR(xHigherPriorityTaskWoken);
  /* USER CODE END dotCallback */
}

/* dashCallback function */
void dashCallback(void *argument)
{
  /* USER CODE BEGIN dashCallback */
  // Notify LED
  BaseType_t xHigherPriorityTaskWoken = pdFALSE;

  vTaskNotifyGiveFromISR(ledTaskNotify, &xHigherPriorityTaskWoken);
  portYIELD_FROM_ISR(xHigherPriorityTaskWoken);
  /* USER CODE END dashCallback */
}

void HAL_TIM_PeriodElapsedCallback(TIM_HandleTypeDef *htim)
{
  if (htim->Instance == TIM6)
  {
    HAL_IncTick();
  }
}

void Error_Handler(void)
{
  /* USER CODE BEGIN Error_Handler_Debug */
  /* User can add his own implementation to report the HAL error return state */
  for (;;)
  {
    HAL_GPIO_TogglePin(GPIOC, GPIO_PIN_5);
    HAL_Delay(200);
    HAL_GPIO_TogglePin(GPIOC, GPIO_PIN_5);
    HAL_GPIO_TogglePin(GPIOE, GPIO_PIN_3);
    HAL_Delay(200);
    HAL_GPIO_TogglePin(GPIOE, GPIO_PIN_3);
  }
  /* USER CODE END Error_Handler_Debug */
}

/************************ (C) COPYRIGHT STMicroelectronics *****END OF FILE****/
